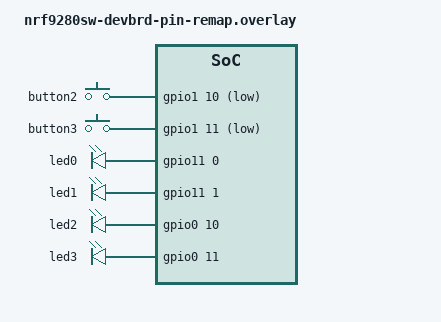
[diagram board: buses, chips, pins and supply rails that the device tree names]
/*
 * Copyright (c) 2024 Nordic Semiconductor ASA
 *
 * SPDX-License-Identifier: LicenseRef-Nordic-5-Clause
 */

/* Not supported. */
/delete-node/ &button0;
/delete-node/ &button1;

/ {
	aliases {
		/delete-property/ sw0;
		/delete-property/ sw1;
	};
};

&button2 {
	gpios = <&gpio1 10 (GPIO_PULL_UP | GPIO_ACTIVE_LOW)>;
};

&button3 {
	gpios = <&gpio1 11 (GPIO_PULL_UP | GPIO_ACTIVE_LOW)>;
};

/* Buttons 2 and 3 use gpio1 pins. Enable gpio1. */
&gpio1 {
	status = "okay";
};

&led0 {
	gpios = <&gpio11 0 GPIO_ACTIVE_HIGH>;
};

&led1 {
	gpios = <&gpio11 1 GPIO_ACTIVE_HIGH>;
};

&led2 {
	gpios = <&gpio0 10 GPIO_ACTIVE_HIGH>;
};

&led3 {
	gpios = <&gpio0 11 GPIO_ACTIVE_HIGH>;
};

/* Leds 0 and 1 use gpio11 pins. Enable gpio11. */
&gpio11 {
	status = "okay";
};

/* gpio11 depends on gpiote131. Enable gpiote131. */
&gpiote131 {
	status = "okay";
};
